# CH32H417 register map
Vendor: WCH Ltd.; File version: 1.2
Registers are 32-bit, read-write, reset 0x0 unless marked. A register's access mark holds for its fields unless they carry their own. Offsets are from the block's base; [hi:lo] are bit positions; {n}, {i} and the like mark numbered series.

## IPC — Inter-cpre communication
Base 0xE000D000
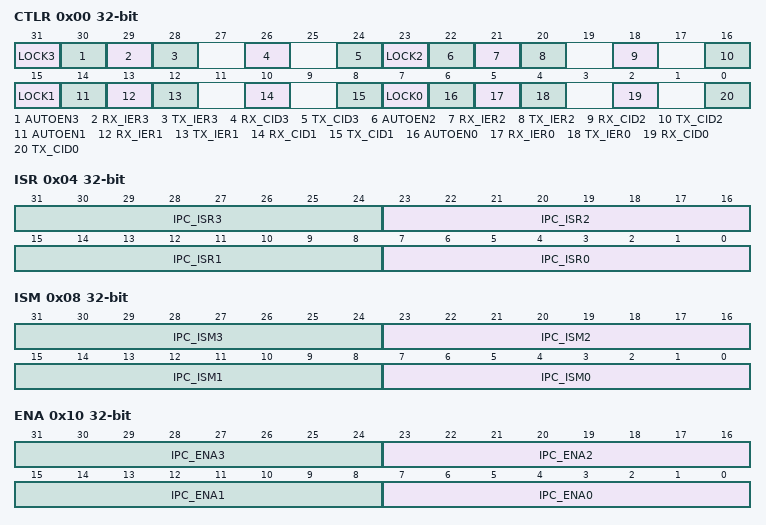
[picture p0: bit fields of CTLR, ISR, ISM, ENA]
0x00 CTLR — IPC control register
  [31] LOCK3 — Channel 3 is locked, and only reset can be cleared after write 1, and other control registers of channel 3 cannot be overridden after locking
  [30] AUTOEN3 — The status bit of channel 3 is automatically updated, when the receiver writes IPC _STS when 1, the IPC_ENA is automatically updated to the same value, and when the receiver writes IPC_SET to the IPC_STS, the corresponding position bit is IPC_ENA when the receiver writes to the IPC_STS
  [29] RX_IER3 — Channel 3 receiver interrupt is enabled, and channel 3 can generate receive interrupt when set to 1
  [28] TX_IER3 — Channel 3 transmitter interrupt is enabled, and channel 3 can generate a transmit interrupt when 1 is set
  [26] RX_CID3 — Receiver kernel ID, configure the kernel that responds to receive interrupts
  [24] TX_CID3 — The ID of the sender kernel and the kernel that responds to the send interrupt
  [23] LOCK2 — Channel 2 configuration locking
  [22] AUTOEN2 — Channel 2 status bits are enabled to be updated automatically
  [21] RX_IER2 — Channel 2 receiver interrupt is enabled, and channel 2 can generate a receive interrupt when 1 is set
  [20] TX_IER2 — Channel 2 transmitter interrupt is enabled, and channel 2 can generate a transmit interrupt when 1 is set
  [18] RX_CID2 — The ID of the kernel on the receiver side, which is configured to respond to the receive interrupt
  [16] TX_CID2 — The ID of the sender kernel to specify the kernel that responds to the sending interrupt
  [15] LOCK1 — Channel 1 configuration locks
  [14] AUTOEN1 — Channel 1 status bits enable automatic updates
  [13] RX_IER1 — Channel 1 receiver interrupt is enabled, and channel 1 can generate receive interrupt when 1 is set
  [12] TX_IER1 — Channel 1 transmitter interrupt is enabled, and channel 1 can generate a transmit interrupt when 1 is set
  [10] RX_CID1 — The ID of the kernel on the receiver side, which is configured to respond to the receive interrupt
  [8] TX_CID1 — The ID of the sender kernel to specify the kernel that responds to the sending interrupt
  [7] LOCK0 — Channel 0 is configured locked
  [6] AUTOEN0 — The channel 0 status bit enables automatic updates
  [5] RX_IER0 — Channel 0 receiver interrupt is enabled, and channel 0 can generate a receive interrupt when 1 is set
  [4] TX_IER0 — Channel 0 transmitter interrupt is enabled, and channel 0 can generate transmit interrupt when set to 1
  [2] RX_CID0 — The ID of the kernel on the receiver side, which is configured to respond to the receive interrupt
  [0] TX_CID0 — The ID of the sender kernel to specify the kernel that responds to the sending interrupt
0x04 ISR ro — IPC interrupt status register
  [8n+7:8n] IPC_ISR{n} (n=0..3) — IPC channel {n} interrupt status register
0x08 ISM ro — IPC ISM channel interrupt mask register
  [8n+7:8n] IPC_ISM{n} (n=0..3) — IPC channel {n} interrupts the mask register
0x10 ENA — IPC status bit interrupt enable register
  [8n+7:8n] IPC_ENA{n} (n=0..3) — IPC channel {n} flag interrupt enable register
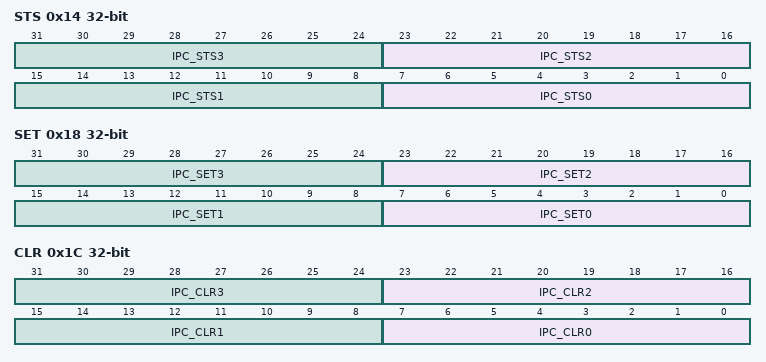
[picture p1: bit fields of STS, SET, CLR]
0x14 STS — IPC channel status registers
  [8n+7:8n] IPC_STS{n} (n=0..3) — IPC channel {n} status register
0x18 SET wo — IPC Status Flag Position Bit Register
  [8n+7:8n] IPC_SET{n} (n=0..3) — IPC channel {n} status flag position bit register
0x1C CLR wo — IPC Status Flag Bit Reset Register
  [8n+7:8n] IPC_CLR{n} (n=0..3) — The status flag of IPC channel {n} clears the register, and the corresponding bit of the IPC _STS register is reset after writing 1
{0x20+4i} MSG{i} (i=0..3) — IPC information register
  [31:0] IPC_MSG{i} — IPC information registers are used to store and transmit information that needs to be passed on for inter-core communication
